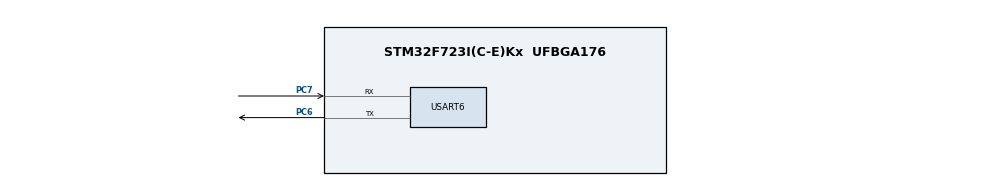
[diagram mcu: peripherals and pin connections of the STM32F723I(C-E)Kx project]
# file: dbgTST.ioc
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Mcu.Family=STM32F7
Mcu.Name=STM32F723I(C-E)Kx
Mcu.Package=UFBGA176
NVIC.PriorityGroup=NVIC_PRIORITYGROUP_4
NVIC.USART6_IRQn=true\:0\:0\:false\:false\:true\:true\:true
PC6.Mode=Asynchronous
PC6.Signal=USART6_TX
PC7.Mode=Asynchronous
PC7.Signal=USART6_RX
ProjectManager.HeapSize=0x200
ProjectManager.StackSize=0x400
ProjectManager.TargetToolchain=EWARM V8
RCC.HSE_VALUE=25000000
RCC.HSI_VALUE=16000000
RCC.LSE_VALUE=32768
RCC.USBFreq_Value=96000000
RCC.VCOOutputFreq_Value=192000000
USART6.OverrunDisableParam=ADVFEATURE_OVERRUN_DISABLE
USART6.VirtualMode-Asynchronous=VM_ASYNC
board=custom

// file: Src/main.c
/* USER CODE BEGIN Header */
/**
  ******************************************************************************
  * @file           : main.c
  * @brief          : Main program body
  ******************************************************************************
  * @attention
  *
  * <h2><center>&copy; Copyright (c) 2020 STMicroelectronics.
  * All rights reserved.</center></h2>
  *
  * This software component is licensed by ST under BSD 3-Clause license,
  * the "License"; You may not use this file except in compliance with the
  * License. You may obtain a copy of the License at:
  *                        opensource.org/licenses/BSD-3-Clause
  *
  ******************************************************************************
  */
/* USER CODE END Header */

#include "main.h"

UART_HandleTypeDef huart6;

void SystemClock_Config(void);
static void MX_GPIO_Init(void);
static void MX_USART6_UART_Init(void);

int main(void)
{

  /* MCU Configuration--------------------------------------------------------*/

  /* Reset of all peripherals, Initializes the Flash interface and the Systick. */
  HAL_Init();

  /* Configure the system clock */
  SystemClock_Config();

  /* Initialize all configured peripherals */
  MX_GPIO_Init();
  MX_USART6_UART_Init();
  /* USER CODE BEGIN 2 */
  SET_BIT(huart6.Instance->CR1, USART_CR1_PEIE | USART_CR1_RXNEIE);

  initDbg();
  //SET_BIT(huart6.Instance->CR1, USART_CR1_TXEIE);
  /* USER CODE END 2 */
    asm("nop");
    asm("nop");
    asm("nop");
    asm("nop");
    asm("nop");
    asm("nop");
    asm("nop");
    asm("nop");

  /* Infinite loop */
  while (1)
  {
    asm("nop");
    asm("nop");
    asm("nop");
    asm("nop");
    asm("nop");
    asm("nop");
    asm("nop");
    asm("nop");
    asm("nop");
    asm("nop");
    asm("nop");
    asm("nop");
    asm("nop");
    asm("nop");
    //asm("BKPT #2");
    asm("nop");
    asm("nop");

    for (int i=0;i<1000000;i++)
      asm("nop");

    HAL_GPIO_TogglePin(GPIOA,GPIO_PIN_7);

  }
}

void SystemClock_Config(void)
{
  RCC_OscInitTypeDef RCC_OscInitStruct = {0};
  RCC_ClkInitTypeDef RCC_ClkInitStruct = {0};
  RCC_PeriphCLKInitTypeDef PeriphClkInitStruct = {0};

  /** Configure the main internal regulator output voltage
  */
  __HAL_RCC_PWR_CLK_ENABLE();
  __HAL_PWR_VOLTAGESCALING_CONFIG(PWR_REGULATOR_VOLTAGE_SCALE3);
  /** Initializes the CPU, AHB and APB busses clocks
  */
  RCC_OscInitStruct.OscillatorType = RCC_OSCILLATORTYPE_HSI;
  RCC_OscInitStruct.HSIState = RCC_HSI_ON;
  RCC_OscInitStruct.HSICalibrationValue = RCC_HSICALIBRATION_DEFAULT;
  RCC_OscInitStruct.PLL.PLLState = RCC_PLL_NONE;
  if (HAL_RCC_OscConfig(&RCC_OscInitStruct) != HAL_OK)
  {
    Error_Handler();
  }
  /** Initializes the CPU, AHB and APB busses clocks
  */
  RCC_ClkInitStruct.ClockType = RCC_CLOCKTYPE_HCLK|RCC_CLOCKTYPE_SYSCLK
                              |RCC_CLOCKTYPE_PCLK1|RCC_CLOCKTYPE_PCLK2;
  RCC_ClkInitStruct.SYSCLKSource = RCC_SYSCLKSOURCE_HSI;
  RCC_ClkInitStruct.AHBCLKDivider = RCC_SYSCLK_DIV1;
  RCC_ClkInitStruct.APB1CLKDivider = RCC_HCLK_DIV1;
  RCC_ClkInitStruct.APB2CLKDivider = RCC_HCLK_DIV1;

  if (HAL_RCC_ClockConfig(&RCC_ClkInitStruct, FLASH_LATENCY_0) != HAL_OK)
  {
    Error_Handler();
  }
  PeriphClkInitStruct.PeriphClockSelection = RCC_PERIPHCLK_USART6;
  PeriphClkInitStruct.Usart6ClockSelection = RCC_USART6CLKSOURCE_PCLK2;
  if (HAL_RCCEx_PeriphCLKConfig(&PeriphClkInitStruct) != HAL_OK)
  {
    Error_Handler();
  }
}

static void MX_USART6_UART_Init(void)
{

  huart6.Instance = USART6;
  huart6.Init.BaudRate = 115200;
  huart6.Init.WordLength = UART_WORDLENGTH_8B;
  huart6.Init.StopBits = UART_STOPBITS_1;
  huart6.Init.Parity = UART_PARITY_NONE;
  huart6.Init.Mode = UART_MODE_TX_RX;
  huart6.Init.HwFlowCtl = UART_HWCONTROL_NONE;
  huart6.Init.OverSampling = UART_OVERSAMPLING_16;
  huart6.Init.OneBitSampling = UART_ONE_BIT_SAMPLE_DISABLE;
  huart6.AdvancedInit.AdvFeatureInit = UART_ADVFEATURE_RXOVERRUNDISABLE_INIT;
  huart6.AdvancedInit.OverrunDisable = UART_ADVFEATURE_OVERRUN_DISABLE;
  if (HAL_UART_Init(&huart6) != HAL_OK)
  {
    Error_Handler();
  }

}

static void MX_GPIO_Init(void)
{

  /* GPIO Ports Clock Enable */
  __HAL_RCC_GPIOA_CLK_ENABLE();
  __HAL_RCC_GPIOC_CLK_ENABLE();

  GPIO_InitTypeDef GPIO_InitStruct = {0};
  GPIO_InitStruct.Pin = GPIO_PIN_7;
  GPIO_InitStruct.Mode = GPIO_MODE_OUTPUT_PP;
  GPIO_InitStruct.Pull = GPIO_NOPULL;
  GPIO_InitStruct.Speed = GPIO_SPEED_FREQ_VERY_HIGH;
  HAL_GPIO_Init(GPIOA, &GPIO_InitStruct);

}

void Error_Handler(void)
{
}

/************************ (C) COPYRIGHT STMicroelectronics *****END OF FILE****/
